# NUC1261AE_v1 register map
File version: 1.0
Registers are 32-bit, read-write, reset 0x0 unless marked. A register's access mark holds for its fields unless they carry their own. Offsets are from the block's base; [hi:lo] are bit positions; lines under a group give offsets from that group; {n}, {i} and the like mark numbered series; 'fields as' and 'values as' point back to an identical list.

## PWM0 — PWM Register Map
Base 0x40040000
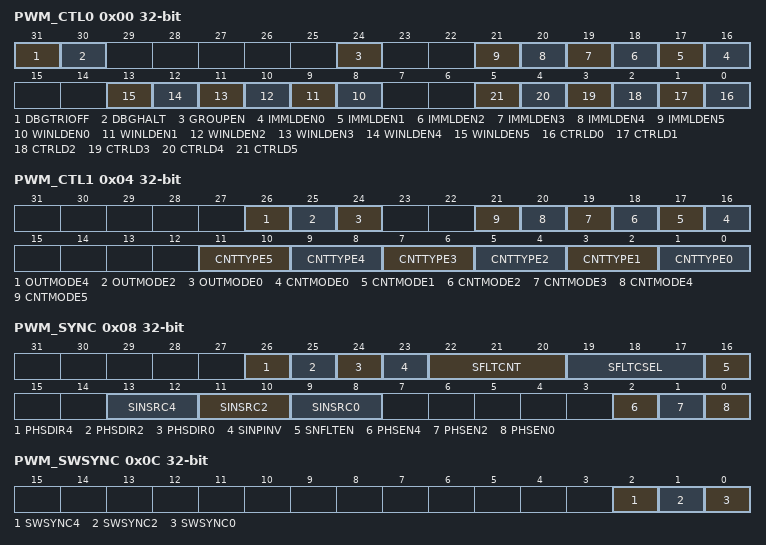
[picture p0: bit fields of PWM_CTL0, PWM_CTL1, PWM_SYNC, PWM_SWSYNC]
0x00 PWM_CTL0 — PWM Control Register 0
  [31] DBGTRIOFF — ICE Debug Mode Acknowledge Disable (Write Protect). PWM pin will keep output no matter ICE debug mode acknowledged or not. Note: This bit is write protected. Refer to SYS_REGLCTL register.
    0=ICE debug mode acknowledgement effects PWM output; 1=ICE debug mode acknowledgement Disabled
  [30] DBGHALT — ICE Debug Mode Counter Halt (Write Protect). If counter halt is enabled, PWM all counters will keep current value until exit ICE debug mode. Note: This bit is write protected. Refer to SYS_REGLCTL register.
    0=ICE debug mode counter halt Disabled; 1=ICE debug mode counter halt Enabled
  [24] GROUPEN — Group Function Enable Bit
    0=The output waveform of each PWM channel are independent; 1=Unify the PWMx_CH2 and PWMx_CH4 to output the same waveform as PWMx_CH0 and unify the PWMx_CH3 and PWMx_CH5 to output the same waveform as PWMx_CH1
  [n+16] IMMLDEN{n} (n=0..5) — Immediately Load Enable Bits. Each bit n controls the corresponding PWM channel n. Note: If IMMLDENn bit is enabled, WINLDENn bit and CTRLDn bits will be invalid.
    0=PERIODn register will load to PBUFn register at the end point of each period. CMPDATn register will load to CMPBUFn register at the end point or center point of each period by setting CTRLDn bit; 1=PERIODn/CMPDATn registers will load to PBUFn and CMPBUFn register immediately when software update PERIODn/CMPDATn register
  [n+8] WINLDEN{n} (n=0..5) — Window Load Enable Bits. Each bit n controls the corresponding PWM channel n.
    0=PERIODn register will load to PBUFn register at the end point of each period. CMPDATn register will load to CMPBUFn register at the end point or center point of each period by setting CTRLDn bit; 1=PERIODn register will load to PBUFn and CMPDATn registers will load to CMPBUFn register at the end point of each period when valid reload window is set. The valid reload window is set by software write 1 to PWM_LOAD register, and cleared by hardware after load success
  [n] CTRLD{n} (n=0..5) — Center Re-load. Each bit n controls the corresponding PWM channel n. In up-down counter type, PERIODn register will load to PBUFn register at the end point of each period. CMPDATn register will load to CMPBUFn register at the center point of a period.
0x04 PWM_CTL1 — PWM Control Register 1
  [26] OUTMODE4 — PWM Output Mode. Each bit n controls the output mode of corresponding PWM channel n. Note: When operating in group function, these bits must all set to the same mode.
    0=PWM independent mode; 1=PWM complementary mode
  [25] OUTMODE2 — PWM Output Mode. Each bit n controls the output mode of corresponding PWM channel n. Note: When operating in group function, these bits must all set to the same mode.
    0=PWM independent mode; 1=PWM complementary mode
  [24] OUTMODE0 — PWM Output Mode. Each bit n controls the output mode of corresponding PWM channel n. Note: When operating in group function, these bits must all set to the same mode.
    0=PWM independent mode; 1=PWM complementary mode
  [n+16] CNTMODE{n} (n=0..5) — PWM Counter Mode. Each bit n controls the corresponding PWM channel n.
    0=Auto-reload mode; 1=One-shot mode
  [2n+1:2n] CNTTYPE{n} (n=0..5) — PWM Counter Behavior Type. Each bit n controls corresponding PWM channel n.
    0=Up counter type (supports in capture mode); 1=Down count type (supports in capture mode); 2=Up-down counter type
0x08 PWM_SYNC — PWM Synchronization Register
  [26] PHSDIR4 — PWM Phase Direction Control. Each bit n controls corresponding PWM channel n.
    0=Control PWM counter count decrement after synchronizing; 1=Control PWM counter count increment after synchronizing
  [25] PHSDIR2 — PWM Phase Direction Control. Each bit n controls corresponding PWM channel n.
    values as PHSDIR4
  [24] PHSDIR0 — PWM Phase Direction Control. Each bit n controls corresponding PWM channel n.
    values as PHSDIR4
  [23] SINPINV — SYNC Input Pin Inverse
    0=The state of PWM0_SYNC_IN pin is passed to the negative edge detector; 1=The inversed state of PWM0_SYNC_IN pin is passed to the negative edge detector
  [22:20] SFLTCNT — SYNC Edge Detector Filter Count. The register bits control the counter number of edge detector.
  [19:17] SFLTCSEL — SYNC Edge Detector Filter Clock Selection
    0=Filter clock = HCLK; 1=Filter clock = HCLK/2; 2=Filter clock = HCLK/4; 3=Filter clock = HCLK/8; 4=Filter clock = HCLK/16; 5=Filter clock = HCLK/32; 6=Filter clock = HCLK/64; 7=Filter clock = HCLK/128
  [16] SNFLTEN — PWM0_SYNC_IN Noise Filter Enable Bit
    0=Noise filter of input PWM0_SYNC_IN pin Disabled; 1=Noise filter of input PWM0_SYNC_IN pin Enabled
  [13:12] SINSRC4 — PWM0_SYNC_IN Source Selection. Each bit n controls corresponding PWM channel n.
    0=Synchronize source from SYNC_IN or SWSYNC; 1=Counter equal to 0; 2=Counter equal to PWM_CMPDATm, m denotes 1, 3, 5; 3=SYNC_OUT signal will not be generated
  [11:10] SINSRC2 — PWM0_SYNC_IN Source Selection. Each bit n controls corresponding PWM channel n.
    values as SINSRC4
  [9:8] SINSRC0 — PWM0_SYNC_IN Source Selection. Each bit n controls corresponding PWM channel n.
    values as SINSRC4
  [2] PHSEN4 — SYNC Phase Enable Bits n denotes PWM channel 0,2,4 and m denotes channel 1,3,5.
    0=PWM counter disable to load value of PHS(PWM_PHSn_m[15:0]) bits; 1=PWM counter enable to load value of PHS(PWM_PHSn_m[15:0]) bits
  [1] PHSEN2 — SYNC Phase Enable Bits n denotes PWM channel 0,2,4 and m denotes channel 1,3,5.
    values as PHSEN4
  [0] PHSEN0 — SYNC Phase Enable Bits n denotes PWM channel 0,2,4 and m denotes channel 1,3,5.
    values as PHSEN4
0x0C PWM_SWSYNC — PWM Software Control Synchronization Register
  [2] SWSYNC4 — Software SYNC Function. Each bit n controls corresponding PWM channel n. When SINSRCn (PWM_SYNC[13:8]) is selected to 0, SYNC_OUT source is come from SYNC_IN or this bit.
  [1] SWSYNC2 — Software SYNC Function. Each bit n controls corresponding PWM channel n. When SINSRCn (PWM_SYNC[13:8]) is selected to 0, SYNC_OUT source is come from SYNC_IN or this bit.
  [0] SWSYNC0 — Software SYNC Function. Each bit n controls corresponding PWM channel n. When SINSRCn (PWM_SYNC[13:8]) is selected to 0, SYNC_OUT source is come from SYNC_IN or this bit.
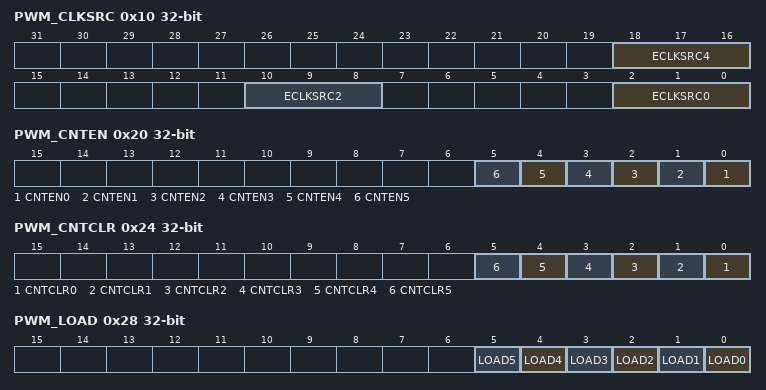
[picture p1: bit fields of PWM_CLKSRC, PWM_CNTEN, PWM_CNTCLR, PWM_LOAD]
0x10 PWM_CLKSRC — PWM Clock Source Register
  [all] fields
    0=PWMx_CLK, x denotes 0 or 1; {v}=TIMER{v-1} time-out event (v=1..4)
  [18:16] ECLKSRC4 — PWMx_CH4/5 External Clock Source Select
  [10:8] ECLKSRC2 — PWMx_CH2/3 External Clock Source Select
  [2:0] ECLKSRC0 — PWMx_CH0/1 External Clock Source Select
0x14 PWM_CLKPSC0_1 — PWM Clock Pre-scale Register 0/1
  [11:0] CLKPSC — PWM Counter Clock Pre-scale. The clock of PWM counter is decided by clock prescaler. Each PWM pair share one PWM counter clock prescaler. The clock of PWM counter is divided by (CLKPSC+ 1).
0x18 PWM_CLKPSC2_3 — PWM Clock Pre-scale Register 2/3
  fields as PWM_CLKPSC0_1
0x1C PWM_CLKPSC4_5 — PWM Clock Pre-scale Register 4/5
  fields as PWM_CLKPSC0_1
0x20 PWM_CNTEN — PWM Counter Enable Register
  [all] fields
    0=PWM Counter and clock prescaler Stop Running; 1=PWM Counter and clock prescaler Start Running
  [n] CNTEN{n} (n=0..5) — PWM Counter Enable Bits. Each bit n controls the corresponding PWM channel n.
0x24 PWM_CNTCLR — PWM Clear Counter Register
  [all] fields
    0=No effect; 1=Clear 16-bit PWM counter to 0x0000(CNT(PWM_CNTn[15:0]))
  [n] CNTCLR{n} (n=0..5) — Clear PWM Counter Control Bit. It is automatically cleared by hardware. Each bit n controls the corresponding PWM channel n.
0x28 PWM_LOAD
  [all] fields
    0=No effect. No load window is set; 1=Set load window of window loading mode. Load window is set
  [n] LOAD{n} (n=0..5) — Re-load PWM Comparator Register (CMPDAT) Control Bit. This bit is software write, and hardware clear when current PWM period end. Each bit n controls the corresponding PWM channel n. Write Operation:
{0x30+4i} PWM_PERIOD{i} (i=0..5) — PWM Period Register {i}
  [15:0] PERIOD — PWM Period Register. Up-Count mode: In this mode, PWM counter counts from 0 to PERIOD, and restarts from 0.
{0x50+4i} PWM_CMPDAT{i} (i=0..5) — PWM Comparator Register {i}
  [15:0] CMP — PWM Comparator Register. CMP bits use to compare with CNT(PWM_CNTn[15:0]) bits to generate PWM waveform, interrupt and trigger ADC. In independent mode, CMPDAT0~5 registers denote as 6 independent PWMx_CH0~5 compared point. In complementary mode, CMPDAT0, 2, 4 registers denote as first compared point, and CMPDAT1, 3, 5 register denote as second compared point for the corresponding 3 complementary pairs PWMx_CH0 and PWMx_CH1, PWMx_CH2 and PWMx_CH3, PWMx_CH4 and PWMx_CH5.
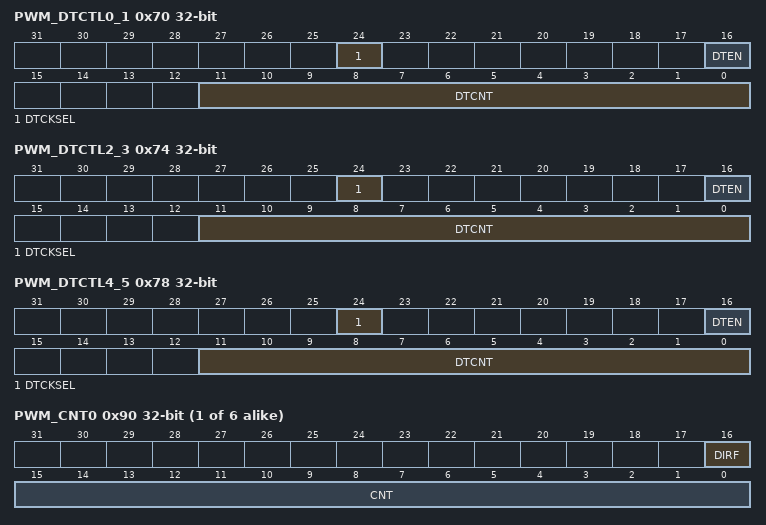
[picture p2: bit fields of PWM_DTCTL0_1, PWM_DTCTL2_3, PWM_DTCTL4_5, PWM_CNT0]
0x70 PWM_DTCTL0_1 — PWM Dead-time Control Register 0/1
  [24] DTCKSEL — Dead-time Clock Select (Write Protect). Note: This register is write protected. Refer to SYS_REGLCTL register.
    0=Dead-time clock source from PWMx_CLK without counter clock prescale; 1=Dead-time clock source from prescaler output with counter clock prescale
  [16] DTEN — Enable Dead-time Insertion for PWM Pair (PWMx_CH0, PWMx_CH1) (PWMx_CH2, PWMx_CH3) (PWMx_CH4, PWMx_CH5) (Write Protect). Dead-time insertion is only active when this pair of complementary PWM is enabled. If dead- time insertion is inactive, the outputs of pin pair are complementary without any delay. Note: This register is write protected. Refer to SYS_REGLCTL register.
    0=Dead-time insertion Disabled on the pin pair; 1=Dead-time insertion Enabled on the pin pair
  [11:0] DTCNT — Dead-time Counter (Write Protect). The dead-time can be calculated from the following formula: Note: This register is write protected. Refer to SYS_REGLCTL register.
0x74 PWM_DTCTL2_3 — PWM Dead-time Control Register 2/3
  fields as PWM_DTCTL0_1
0x78 PWM_DTCTL4_5 — PWM Dead-time Control Register 4/5
  fields as PWM_DTCTL0_1
0x80 PWM_PHS0_1 — PWM Counter Phase Register 0/1
  [15:0] PHS — PWM Synchronous Start Phase Bits. PHS bits determines the PWM synchronous start phase value. These bits only use in synchronous function.
0x84 PWM_PHS2_3 — PWM Counter Phase Register 2/3
  fields as PWM_PHS0_1
0x88 PWM_PHS4_5 — PWM Counter Phase Register 4/5
  fields as PWM_PHS0_1
{0x90+4i} PWM_CNT{i} ro (i=0..5) — PWM Counter Register {i}
  [16] DIRF — PWM Direction Indicator Flag (Read Only)
    0=Counter is Down count; 1=Counter is UP count
  [15:0] CNT — PWM Counter Data Bits (Read Only). User can monitor CNT to know the current value in 16-bit period counter.
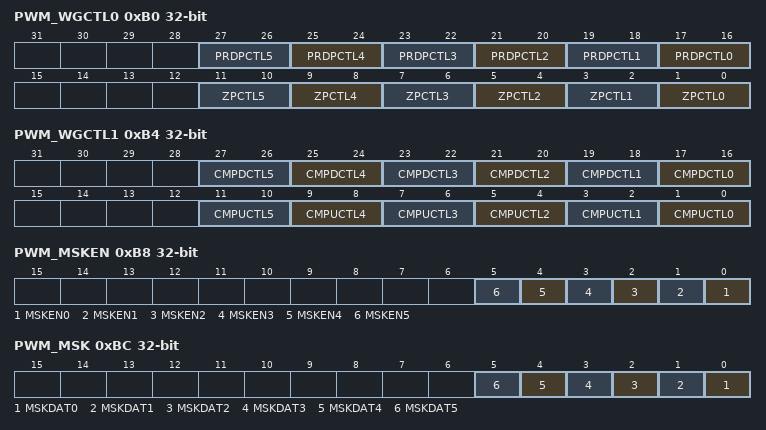
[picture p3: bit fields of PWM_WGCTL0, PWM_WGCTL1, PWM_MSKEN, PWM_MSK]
0xB0 PWM_WGCTL0 — PWM Generation Register 0
  [2n+17:2n+16] PRDPCTL{n} (n=0..5) — PWM Period (Center) Point Control. PWM can control output level on period(center) point event. Each bit n controls the corresponding PWM channel n. Note: This bit is center point control when PWM counter operating in up-down counter type.
    0=Do nothing; 1=PWM period (center) point output Low; 2=PWM period (center) point output High; 3=PWM period (center) point output Toggle
  [2n+1:2n] ZPCTL{n} (n=0..5) — PWM Zero Point Control. PWM can control output level on zero point event. Each bit n controls the corresponding PWM channel n.
    0=Do nothing; 1=PWM zero point output Low; 2=PWM zero point output High; 3=PWM zero point output Toggle
0xB4 PWM_WGCTL1 — PWM Generation Register 1
  [2n+17:2n+16] CMPDCTL{n} (n=0..5) — PWM Compare Down Point Control. PWM can control output level on compare down point event. Each bit n controls the corresponding PWM channel n. Note: In complementary mode, CMPDCTL1, 3, 5 is used as another CMPDCTL for channel 0, 2, 4.
    0=Do nothing; 1=PWM compare down point output Low; 2=PWM compare down point output High; 3=PWM compare down point output Toggle
  [2n+1:2n] CMPUCTL{n} (n=0..5) — PWM Compare Up Point Control. PWM can control output level on compare up point event. Each bit n controls the corresponding PWM channel n. Note: In complementary mode, CMPUCTL1, 3, 5 is used as another CMPUCTL for channel 0, 2, 4.
    0=Do nothing; 1=PWM compare up point output Low; 2=PWM compare up point output High; 3=PWM compare up point output Toggle
0xB8 PWM_MSKEN — PWM Mask Enable Register
  [all] fields
    0=PWM output signal is non-masked; 1=PWM output signal is masked and output MSKDATn data
  [n] MSKEN{n} (n=0..5) — PWM Mask Enable Bits. The PWM output signal will be masked when this bit is enabled. The corresponding PWM channel n will output MSKDATn (PWM_MSK[5:0]) data. Each bit n controls the corresponding PWM channel n.
0xBC PWM_MSK — PWM Mask Data Register
  [all] fields
    0=Output logic low to PWMx_CHn; 1=Output logic high to PWMx_CHn
  [n] MSKDAT{n} (n=0..5) — PWM Mask Data Bit. This data bit control the state of PWMx_CHn output pin, if corresponding mask function is enabled. Each bit n controls the corresponding PWM channel n.
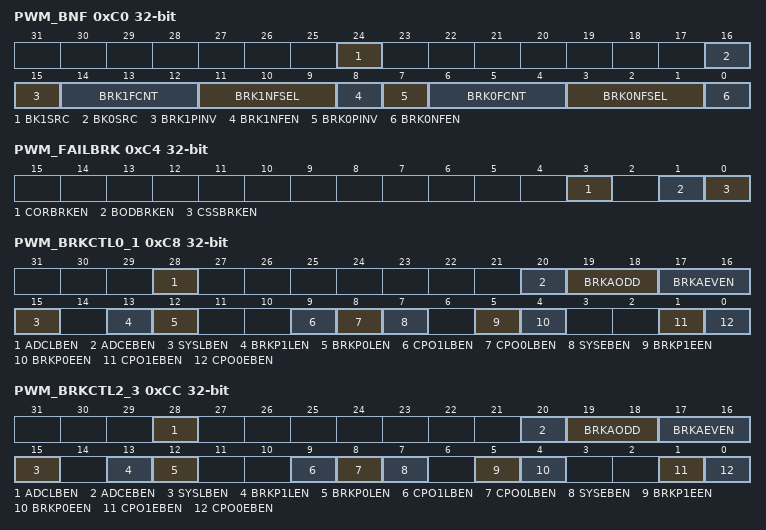
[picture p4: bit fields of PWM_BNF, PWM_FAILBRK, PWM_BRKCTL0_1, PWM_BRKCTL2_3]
0xC0 PWM_BNF — PWM Brake Noise Filter Register
  [24] BK1SRC — Brake 1 Pin Source Select. For PWM0 setting:
    0=Brake 1 pin source come from PWM0_BRAKE1. Brake 1 pin source come from PWM1_BRAKE1; 1=Brake 1 pin source come from PWM1_BRAKE1. Brake 1 pin source come from PWM0_BRAKE1
  [16] BK0SRC — Brake 0 Pin Source Select. For PWM0 setting:
    0=Brake 0 pin source come from PWM0_BRAKE0. Brake 0 pin source come from PWM1_BRAKE0; 1=Brake 0 pin source come from PWM1_BRAKE0. Brake 0 pin source come from PWM0_BRAKE0
  [15] BRK1PINV — Brake 1 Pin Inverse
    0=Brake pin event will be detected if PWM1_BRAKEx pin status transfer from low to high in edge-detect, or pin status is high in level-detect; 1=Brake pin event will be detected if PWM1_BRAKEx pin status transfer from high to low in edge-detect, or pin status is low in level-detect
  [14:12] BRK1FCNT — Brake 1 Edge Detector Filter Count. The register bits control the Brake1 filter counter to count from 0 to BRK1FCNT.
  [11:9] BRK1NFSEL — Brake 1 Edge Detector Filter Clock Selection
    values as PWM_SYNC.SFLTCSEL
  [8] BRK1NFEN — PWM Brake 1 Noise Filter Enable Bit
    0=Noise filter of PWM Brake 1 Disabled; 1=Noise filter of PWM Brake 1 Enabled
  [7] BRK0PINV — Brake 0 Pin Inverse
    0=Brake pin event will be detected if PWM0_BRAKEx pin status transfer from low to high in edge-detect, or pin status is high in level-detect; 1=Brake pin event will be detected if PWM0_BRAKEx pin status transfer from high to low in edge-detect, or pin status is low in level-detect
  [6:4] BRK0FCNT — Brake 0 Edge Detector Filter Count. The register bits control the Brake0 filter counter to count from 0 to BRK0FCNT.
  [3:1] BRK0NFSEL — Brake 0 Edge Detector Filter Clock Selection
    values as PWM_SYNC.SFLTCSEL
  [0] BRK0NFEN — PWM Brake 0 Noise Filter Enable Bit
    0=Noise filter of PWM Brake 0 Disabled; 1=Noise filter of PWM Brake 0 Enabled
0xC4 PWM_FAILBRK — PWM System Fail Brake Control Register
  [3] CORBRKEN — Core Lockup Detection Trigger PWM Brake Function Enable Bit
    0=Brake Function triggered by Core lockup event Disabled; 1=Brake Function triggered by Core lockup event Enabled
  [1] BODBRKEN — Brown-out Detection Trigger PWM Brake Function Enable Bit
    0=Brake Function triggered by BOD event Disabled; 1=Brake Function triggered by BOD event Enabled
  [0] CSSBRKEN — Clock Security System Detection Trigger PWM Brake Function Enable Bit
    0=Brake Function triggered by clock fail detection Disabled; 1=Brake Function triggered by clock fail detection Enabled
0xC8 PWM_BRKCTL0_1 — PWM Brake Edge Detect Control Register 0/1
  [28] ADCLBEN — Enable ADC Result Monitor (ADCRM) As Level-detect Brake Source (Write Protect). Note: This register is write protected. Refer to SYS_REGLCTL register.
    0=ADCRM as level-detect brake source Disabled; 1=ADCRM as level-detect brake source Enabled
  [20] ADCEBEN — Enable ADC Result Monitor (ADCRM) As Edge-detect Brake Source (Write Protect). Note: This register is write protected. Refer to SYS_REGLCTL register.
    0=ADCRM as edge-detect brake source Disabled; 1=ADCRM as edge-detect brake source Enabled
  [19:18] BRKAODD — PWM Brake Action Select for Odd Channel (Write Protect). Note: This register is write protected. Refer to SYS_REGLCTL register.
    0=PWMx brake event will not affect odd channels output; 1=PWM odd channel output tri-state when PWMx brake event happened; 2=PWM odd channel output low level when PWMx brake event happened; 3=PWM odd channel output high level when PWMx brake event happened
  [17:16] BRKAEVEN — PWM Brake Action Select for Even Channel (Write Protect). Note: This register is write protected. Refer to SYS_REGLCTL register.
    0=PWMx brake event will not affect even channels output; 1=PWM even channel output tri-state when PWMx brake event happened; 2=PWM even channel output low level when PWMx brake event happened; 3=PWM even channel output high level when PWMx brake event happened
  [15] SYSLBEN — Enable System Fail As Level-detect Brake Source (Write Protect). Note: This register is write protected. Refer to SYS_REGLCTL register.
    0=System Fail condition as level-detect brake source Disabled; 1=System Fail condition as level-detect brake source Enabled
  [13] BRKP1LEN — Enable BKP1 Pin As Level-detect Brake Source (Write Protect). Note: This register is write protected. Refer to SYS_REGLCTL register.
    0=PWMx_BRAKE1 pin as level-detect brake source Disabled; 1=PWMx_BRAKE1 pin as level-detect brake source Enabled
  [12] BRKP0LEN — Enable BKP0 Pin As Level-detect Brake Source (Write Protect). Note: This register is write protected. Refer to SYS_REGLCTL register.
    0=PWMx_BRAKE0 pin as level-detect brake source Disabled; 1=PWMx_BRAKE0 pin as level-detect brake source Enabled
  [9] CPO1LBEN — Enable ACMP1_O Digital Output As Level-detect Brake Source (Write Protect). Note: This register is write protected. Refer to SYS_REGLCTL register.
    0=ACMP1_O as level-detect brake source Disabled; 1=ACMP1_O as level-detect brake source Enabled
  [8] CPO0LBEN — Enable ACMP0_O Digital Output As Level-detect Brake Source (Write Protect). Note: This register is write protected. Refer to SYS_REGLCTL register.
    0=ACMP0_O as level-detect brake source Disabled; 1=ACMP0_O as level-detect brake source Enabled
  [7] SYSEBEN — Enable System Fail As Edge-detect Brake Source (Write Protect). Note: This register is write protected. Refer to SYS_REGLCTL register.
    0=System Fail condition as edge-detect brake source Disabled; 1=System Fail condition as edge-detect brake source Enabled
  [5] BRKP1EEN — Enable PWMx_BRAKE1 Pin As Edge-detect Brake Source (Write Protect). Note: This register is write protected. Refer to SYS_REGLCTL register.
    0=PWMx_BRAKE1 pin as edge-detect brake source Disabled; 1=PWMx_BRAKE1 pin as edge-detect brake source Enabled
  [4] BRKP0EEN — Enable PWMx_BRAKE0 Pin As Edge-detect Brake Source (Write Protect). Note: This register is write protected. Refer to SYS_REGLCTL register.
    0=PWMx_BRAKE0 pin as edge-detect brake source Disabled; 1=PWMx_BRAKE0 pin as edge-detect brake source Enabled
  [1] CPO1EBEN — Enable ACMP1_O Digital Output As Edge-detect Brake Source (Write Protect). Note: This register is write protected. Refer to SYS_REGLCTL register.
    0=ACMP1_O as edge-detect brake source Disabled; 1=ACMP1_O as edge-detect brake source Enabled
  [0] CPO0EBEN — Enable ACMP0_O Digital Output As Edge-detect Brake Source (Write Protect). Note: This register is write protected. Refer to SYS_REGLCTL register.
    0=ACMP0_O as edge-detect brake source Disabled; 1=ACMP0_O as edge-detect brake source Enabled
0xCC PWM_BRKCTL2_3 — PWM Brake Edge Detect Control Register 2/3
  fields as PWM_BRKCTL0_1
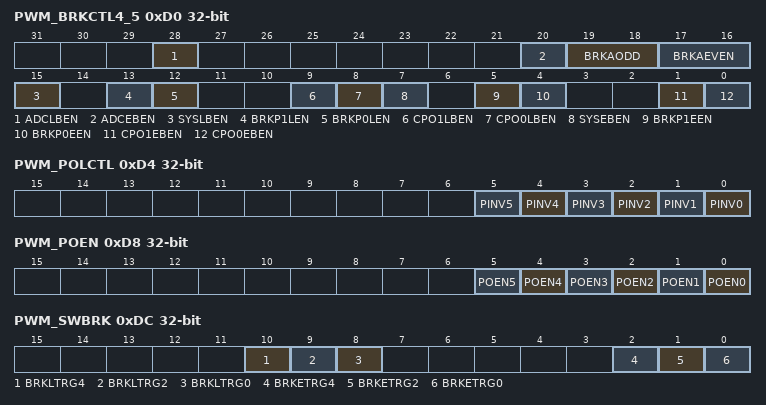
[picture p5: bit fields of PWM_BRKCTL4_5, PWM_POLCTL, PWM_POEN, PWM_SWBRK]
0xD0 PWM_BRKCTL4_5 — PWM Brake Edge Detect Control Register 4/5
  fields as PWM_BRKCTL0_1
0xD4 PWM_POLCTL — PWM Pin Polar Inverse Register
  [all] fields
    0=PWMx_CHn output pin polar inverse Disabled; 1=PWMx_CHn output pin polar inverse Enabled
  [n] PINV{n} (n=0..5) — PWM PIN Polar Inverse Control. The register controls polarity state of PWMx_CHn output pin. Each bit n controls the corresponding PWM channel n.
0xD8 PWM_POEN — PWM Output Enable Register
  [all] fields
    0=PWMx_CHn pin at tri-state; 1=PWMx_CHn pin in output mode
  [n] POEN{n} (n=0..5) — PWMx_CHn Pin Output Enable Bits. Each bit n controls the corresponding PWM channel n.
0xDC PWM_SWBRK wo — PWM Software Brake Control Register
  [10] BRKLTRG4 — PWM Level Brake Software Trigger (Write Only) (Write Protect). Write 1 to this bit will trigger level brake, and set BRKLIFn bits to 1 in PWM_INTSTS1 register. Each bit n controls the corresponding PWM pair n. Note: This register is write protected. Refer to SYS_REGLCTL register.
  [9] BRKLTRG2 — PWM Level Brake Software Trigger (Write Only) (Write Protect). Write 1 to this bit will trigger level brake, and set BRKLIFn bits to 1 in PWM_INTSTS1 register. Each bit n controls the corresponding PWM pair n. Note: This register is write protected. Refer to SYS_REGLCTL register.
  [8] BRKLTRG0 — PWM Level Brake Software Trigger (Write Only) (Write Protect). Write 1 to this bit will trigger level brake, and set BRKLIFn bits to 1 in PWM_INTSTS1 register. Each bit n controls the corresponding PWM pair n. Note: This register is write protected. Refer to SYS_REGLCTL register.
  [2] BRKETRG4 — PWM Edge Brake Software Trigger (Write Only) (Write Protect). Write 1 to this bit will trigger Edge brake, and set BRKEIFn bits to 1 in PWM_INTSTS1 register. Each bit n controls the corresponding PWM pair n. Note: This register is write protected. Refer to REGWRPROT register.
  [1] BRKETRG2 — PWM Edge Brake Software Trigger (Write Only) (Write Protect). Write 1 to this bit will trigger Edge brake, and set BRKEIFn bits to 1 in PWM_INTSTS1 register. Each bit n controls the corresponding PWM pair n. Note: This register is write protected. Refer to REGWRPROT register.
  [0] BRKETRG0 — PWM Edge Brake Software Trigger (Write Only) (Write Protect). Write 1 to this bit will trigger Edge brake, and set BRKEIFn bits to 1 in PWM_INTSTS1 register. Each bit n controls the corresponding PWM pair n. Note: This register is write protected. Refer to REGWRPROT register.
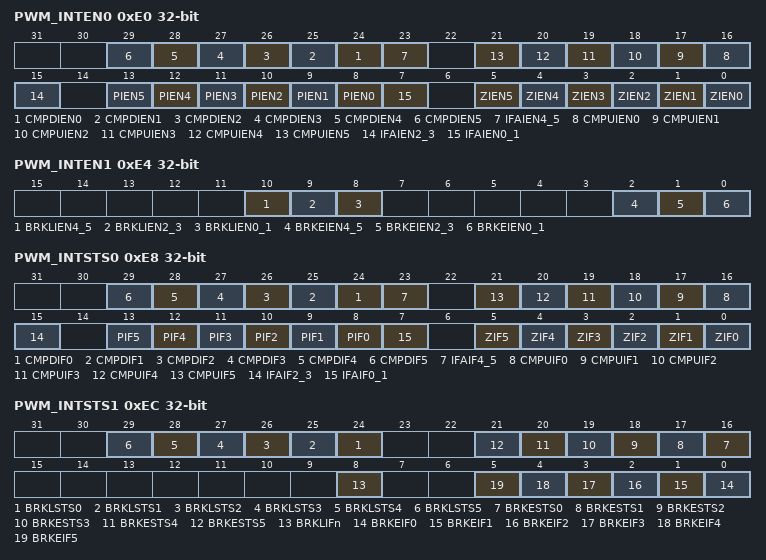
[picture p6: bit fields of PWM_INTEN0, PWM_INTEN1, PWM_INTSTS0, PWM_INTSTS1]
0xE0 PWM_INTEN0 — PWM Interrupt Enable Register 0
  [n+24] CMPDIEN{n} (n=0..5) — PWM Compare Down Count Interrupt Enable Bits. Each bit n controls the corresponding PWM channel n. Note: In complementary mode, CMPDIEN1, 3, 5 is used as another CMPDIEN for channel 0, 2, 4.
    0=Compare down count interrupt Disabled; 1=Compare down count interrupt Enabled
  [23] IFAIEN4_5 — PWM Channel 4/5 Interrupt Flag Accumulator Interrupt Enable Bit
    0=Interrupt Flag accumulator interrupt Disabled; 1=Interrupt Flag accumulator interrupt Enabled
  [n+16] CMPUIEN{n} (n=0..5) — PWM Compare Up Count Interrupt Enable Bits. Each bit n controls the corresponding PWM channel n. Note: In complementary mode, CMPUIEN1, 3, 5 is used as another CMPUIEN for channel 0, 2, 4.
    0=Compare up count interrupt Disabled; 1=Compare up count interrupt Enabled
  [15] IFAIEN2_3 — PWM Channel 2/3 Interrupt Flag Accumulator Interrupt Enable Bit
    values as IFAIEN4_5
  [n+8] PIEN{n} (n=0..5) — PWM Period Point Interrupt Enable Bits. Each bit n controls the corresponding PWM channel n. Note1: When up-down counter type period point means center point. Note2: Odd channels will read always 0 at complementary mode.
    0=Period point interrupt Disabled; 1=Period point interrupt Enabled
  [7] IFAIEN0_1 — PWM Channel 0/1 Interrupt Flag Accumulator Interrupt Enable Bit
    values as IFAIEN4_5
  [n] ZIEN{n} (n=0..5) — PWM Zero Point Interrupt Enable Bits. Each bit n controls the corresponding PWM channel n. Note: Odd channels will read always 0 at complementary mode.
    0=Zero point interrupt Disabled; 1=Zero point interrupt Enabled
0xE4 PWM_INTEN1 — PWM Interrupt Enable Register 1
  [10] BRKLIEN4_5 — PWM Level-detect Brake Interrupt Enable for Channel4/5 (Write Protect). Note: This register is write protected. Refer to SYS_REGLCTL register.
    0=Level-detect Brake interrupt for channel4/5 Disabled; 1=Level-detect Brake interrupt for channel4/5 Enabled
  [9] BRKLIEN2_3 — PWM Level-detect Brake Interrupt Enable for Channel2/3 (Write Protect). Note: This register is write protected. Refer to SYS_REGLCTL register.
    0=Level-detect Brake interrupt for channel2/3 Disabled; 1=Level-detect Brake interrupt for channel2/3 Enabled
  [8] BRKLIEN0_1 — PWM Level-detect Brake Interrupt Enable for Channel0/1 (Write Protect). Note: This register is write protected. Refer to SYS_REGLCTL register.
    0=Level-detect Brake interrupt for channel0/1 Disabled; 1=Level-detect Brake interrupt for channel0/1 Enabled
  [2] BRKEIEN4_5 — PWM Edge-detect Brake Interrupt Enable for Channel4/5 (Write Protect). Note: This register is write protected. Refer to SYS_REGLCTL register.
    0=Edge-detect Brake interrupt for channel4/5 Disabled; 1=Edge-detect Brake interrupt for channel4/5 Enabled
  [1] BRKEIEN2_3 — PWM Edge-detect Brake Interrupt Enable for Channel2/3 (Write Protect). Note: This register is write protected. Refer to SYS_REGLCTL register.
    0=Edge-detect Brake interrupt for channel2/3 Disabled; 1=Edge-detect Brake interrupt for channel2/3 Enabled
  [0] BRKEIEN0_1 — PWM Edge-detect Brake Interrupt Enable for Channel0/1 (Write Protect). Note: This register is write protected. Refer to SYS_REGLCTL register.
    0=Edge-detect Brake interrupt for channel0/1 Disabled; 1=Edge-detect Brake interrupt for channel0/1 Enabled
0xE8 PWM_INTSTS0 — PWM Interrupt Flag Register 0
  [n+24] CMPDIF{n} (n=0..5) — PWM Compare Down Count Interrupt Flag. Flag is set by hardware when PWM counter down count and reaches CMP(PWM_CMPDATn[15:0]), software can clear this bit by writing 1 to it. Each bit n controls the corresponding PWM channel n. Note1: If CMP equal to PERIOD, this flag is not working in down counter type selection. Note2: In complementary mode, CMPDIF1, 3, 5 is used as another CMPDIF for channel 0, 2, 4.
  [23] IFAIF4_5 — PWM Channel 4/5 Interrupt Flag Accumulator Interrupt Flag. Flag is set by hardware when condition match IFSEL4_5 bits in PWM_IFA register, software can clear this bit by writing 1 to it.
  [n+16] CMPUIF{n} (n=0..5) — PWM Compare Up Count Interrupt Flag. Flag is set by hardware when PWM counter up count and reaches CMP(PWM_CMPDATn[15:0]), software can clear this bit by writing 1 to it. Each bit n controls the corresponding PWM channel n. Note1: If CMP equal to PERIOD, this flag is not working in up counter type selection. Note2: In complementary mode, CMPUIF1, 3, 5 is used as another CMPUIF for channel 0, 2, 4.
  [15] IFAIF2_3 — PWM Channel 2/3 Interrupt Flag Accumulator Interrupt Flag. Flag is set by hardware when condition match IFSEL2_3 bits in PWM_IFA register, software can clear this bit by writing 1 to it.
  [n+8] PIF{n} (n=0..5) — PWM Period Point Interrupt Flag. This bit is set by hardware when PWM counter reaches PERIOD(PWM_PERIODn[15:0]), software can write 1 to clear this bit to zero. Each bit n controls the corresponding PWM channel n.
  [7] IFAIF0_1 — PWM Channel 0/1 Interrupt Flag Accumulator Interrupt Flag. Flag is set by hardware when condition match IFSEL0_1 bits in PWM_IFA register, software can clear this bit by writing 1 to it.
  [n] ZIF{n} (n=0..5) — PWM Zero Point Interrupt Flag. Each bit n controls the corresponding PWM channel n. This bit is set by hardware when PWM counter reaches zero, software can write 1 to clear this bit to zero.
0xEC PWM_INTSTS1 — PWM Interrupt Flag Register 1
  [n+24] BRKLSTS{n} ro (n=0..5) — PWM Channel n Level-detect Brake Status (Read Only). Note: This bit is read only and auto cleared by hardware. When enabled brake source return to high level, PWM will release brake state until current PWM period finished. The PWM waveform will start output from next full PWM period.
    0=PWM channel n level-detect brake state is released; 1=When PWM channel n level-detect brake detects a falling edge of any enabled brake source; this flag will be set to indicate the PWM channel n at brake state
  [n+16] BRKESTS{n} (n=0..5) — PWM Channel n Edge-detect Brake Status
    0=PWM channel n edge-detect brake state is released; 1=When PWM channel n edge-detect brake detects a falling edge of any enabled brake source; this flag will be set to indicate the PWM channel n at brake state, writing 1 to clear
  [8] BRKLIFn — PWM Channel n Level-detect Brake Interrupt Flag (Write Protect). Note: This bit is write protected. Refer to SYS_REGLCTL register.
    0=PWM channel n level-detect brake event do not happened; 1=When PWM channel n level-detect brake event happened, this bit is set to 1, writing 1 to clear
  [n] BRKEIF{n} (n=0..5) — PWM Channel n Edge-detect Brake Interrupt Flag (Write Protect). Note: This bit is write protected. Refer to SYS_REGLCTL register.
    0=PWM channel n edge-detect brake event do not happened; 1=When PWM channel n edge-detect brake event happened, this bit is set to 1, writing 1 to clear
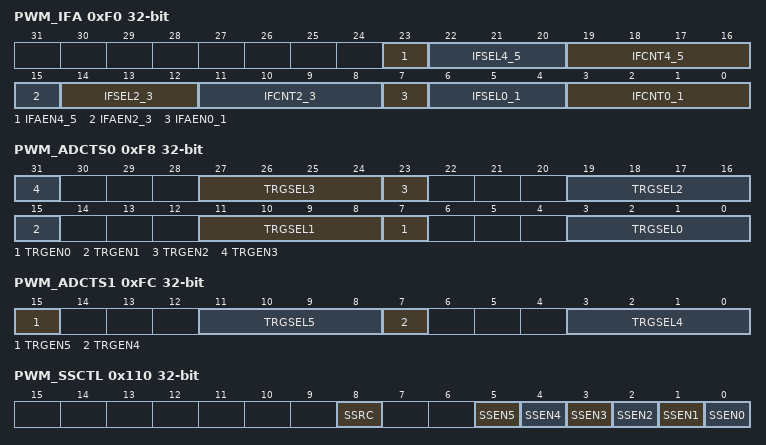
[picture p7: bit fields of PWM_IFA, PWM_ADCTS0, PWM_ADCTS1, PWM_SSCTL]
0xF0 PWM_IFA — PWM Interrupt Flag Accumulator Register
  [23] IFAEN4_5 — PWM Channel 4/5 Interrupt Flag Accumulator Enable Bit
    0=PWM Channel 4/5 interrupt flag accumulator Disabled; 1=PWM Channel 4/5 interrupt flag accumulator Enabled
  [22:20] IFSEL4_5 — PWM Channel 4/5 Interrupt Flag Accumulator Source Select
    0=CNT equal to Zero in channel 4; 1=CNT equal to PERIOD in channel 4; 2=CNT equal to CMPU in channel 4; 3=CNT equal to CMPD in channel 4; 4=CNT equal to Zero in channel 5; 5=CNT equal to PERIOD in channel 5; 6=CNT equal to CMPU in channel 5; 7=CNT equal to CMPD in channel 5
  [19:16] IFCNT4_5 — PWM Channel 4/5 Interrupt Flag Counter. The register sets the count number which defines how many times of PWM Channel 4/5 period occurs to set IFAIF4_5 bit to request the PWM period interrupt. PWM flag will be set in every IFCNT4_5[3:0] times of PWM period.
  [15] IFAEN2_3 — PWM Channel 2/3 Interrupt Flag Accumulator Enable Bit
    0=PWM Channel 2/3 interrupt flag accumulator Disabled; 1=PWM Channel 2/3 interrupt flag accumulator Enabled
  [14:12] IFSEL2_3 — PWM Channel 2/3 Interrupt Flag Accumulator Source Select
    0=CNT equal to Zero in channel 2; 1=CNT equal to PERIOD in channel 2; 2=CNT equal to CMPU in channel 2; 3=CNT equal to CMPD in channel 2; 4=CNT equal to Zero in channel 3; 5=CNT equal to PERIOD in channel 3; 6=CNT equal to CMPU in channel 3; 7=CNT equal to CMPD in channel 3
  [11:8] IFCNT2_3 — PWM Channel 2/3 Interrupt Flag Counter. The register sets the count number which defines how many times of PWM Channel 2/3 period occurs to set IFAIF2_3 bit to request the PWM period interrupt. PWM flag will be set in every IFCNT2_3[3:0] times of PWM period.
  [7] IFAEN0_1 — PWM Channel 0/1 Interrupt Flag Accumulator Enable Bit
    0=PWM Channel 0/1 interrupt flag accumulator Disabled; 1=PWM Channel 0/1 interrupt flag accumulator Enabled
  [6:4] IFSEL0_1 — PWM Channel 0/1 Interrupt Flag Accumulator Source Select
    0=CNT equal to Zero in channel 0; 1=CNT equal to PERIOD in channel 0; 2=CNT equal to CMPU in channel 0; 3=CNT equal to CMPD in channel 0; 4=CNT equal to Zero in channel 1; 5=CNT equal to PERIOD in channel 1; 6=CNT equal to CMPU in channel 1; 7=CNT equal to CMPD in channel 1
  [3:0] IFCNT0_1 — PWM Channel 0/1 Interrupt Flag Counter. The register sets the count number which defines how many times of PWM Channel 0/1 period occurs to set IFAIF0_1 bit to request the PWM period interrupt. PWM flag will be set in every IFCNT0_1 [3:0] times of PWM period.
0xF8 PWM_ADCTS0 — PWM Trigger ADC Source Select Register 0
  [8n+7] TRGEN{n} (n=0..3) — PWM_CH{n} Trigger ADC enable bit
  [27:24] TRGSEL3 — PWM_CH3 Trigger ADC Source Select
    0=PWM_CH2 zero point; 1=PWM_CH2 period point; 2=PWM_CH2 zero or period point; 3=PWM_CH2 up-count compared point; 4=PWM_CH2 down-count compared point; 5=PWM_CH3 zero point; 6=PWM_CH3 period point; 7=PWM_CH3 zero or period point; 8=PWM_CH3 up-count compared point; 9=PWM_CH3 down-count compared point; 10=PWM_CH0 up-count free trigger compared point; 11=PWM_CH0 down-count free trigger compared point; 12=PWM_CH2 up-count free trigger compared point; 13=PWM_CH2 down-count free trigger compared point; 14=PWM_CH4 up-count free trigger compared point; 15=PWM_CH4 down-count free trigger compared point
  [19:16] TRGSEL2 — PWM_CH2 Trigger ADC Source Select
    values as TRGSEL3
  [11:8] TRGSEL1 — PWM_CH1 Trigger ADC Source Select
    0=PWM_CH0 zero point; 1=PWM_CH0 period point; 2=PWM_CH0 zero or period point; 3=PWM_CH0 up-count compared point; 4=PWM_CH0 down-count compared point; 5=PWM_CH1 zero point; 6=PWM_CH1 period point; 7=PWM_CH1 zero or period point; 8=PWM_CH1 up-count compared point; 9=PWM_CH1 down-count compared point; 10=PWM_CH0 up-count free trigger compared point; 11=PWM_CH0 down-count free trigger compared point; 12=PWM_CH2 up-count free trigger compared point; 13=PWM_CH2 down-count free trigger compared point; 14=PWM_CH4 up-count free trigger compared point; 15=PWM_CH4 down-count free trigger compared point
  [3:0] TRGSEL0 — PWM_CH0 Trigger ADC Source Select
    values as TRGSEL1
0xFC PWM_ADCTS1 — PWM Trigger ADC Source Select Register 1
  [15] TRGEN5 — PWM_CH5 Trigger ADC enable bit
  [11:8] TRGSEL5 — PWM_CH5 Trigger ADC Source Select
    0=PWM_CH4 zero point; 1=PWM_CH4 period point; 2=PWM_CH4 zero or period point; 3=PWM_CH4 up-count compared point; 4=PWM_CH4 down-count compared point; 5=PWM_CH5 zero point; 6=PWM_CH5 period point; 7=PWM_CH5 zero or period point; 8=PWM_CH5 up-count compared point; 9=PWM_CH5 down-count compared point; 10=PWM_CH0 up-count free trigger compared point; 11=PWM_CH0 down-count free trigger compared point; 12=PWM_CH2 up-count free trigger compared point; 13=PWM_CH2 down-count free trigger compared point; 14=PWM_CH4 up-count free trigger compared point; 15=PWM_CH4 down-count free trigger compared point
  [7] TRGEN4 — PWM_CH4 Trigger ADC enable bit
  [3:0] TRGSEL4 — PWM_CH4 Trigger ADC Source Select
    values as TRGSEL5
0x100 PWM_FTCMPDAT0_1 — PWM Free Trigger Compare Register 0/1
  [15:0] FTCMP — PWM Free Trigger Compare Register
0x104 PWM_FTCMPDAT2_3 — PWM Free Trigger Compare Register 2/3
  [15:0] FTCMP — PWM Free Trigger Compare Register
0x108 PWM_FTCMPDAT4_5 — PWM Free Trigger Compare Register 4/5
  [15:0] FTCMP — PWM Free Trigger Compare Register
0x110 PWM_SSCTL — PWM Synchronous Start Control Register
  [8] SSRC — PWM Synchronous Start Source Select Bit
    0=Synchronous start source come from PWM0; 1=Synchronous start source come from PWM1
  [n] SSEN{n} (n=0..5) — PWM Synchronous Start Function Enable Bits. When synchronous start function is enabled, the PWM counter enable register (PWM_CNTEN) can be enabled by writing PWM synchronous start trigger bit (CNTSEN). Each bit n controls the corresponding PWM channel n.
    0=PWM synchronous start function Disabled; 1=PWM synchronous start function Enabled
0x114 PWM_SSTRG wo — PWM Synchronous Start Trigger Register
  [0] CNTSEN — PWM Counter Synchronous Start Enable (Write Only). PMW counter synchronous enable function is used to make selected PWM channels (PWMx_CHn) start counting at the same time. Writing this bit to 1 will also set the counter enable bit (CNTENn, n denotes channel 0 to 5) if correlated PWM channel counter synchronous start function is enabled.
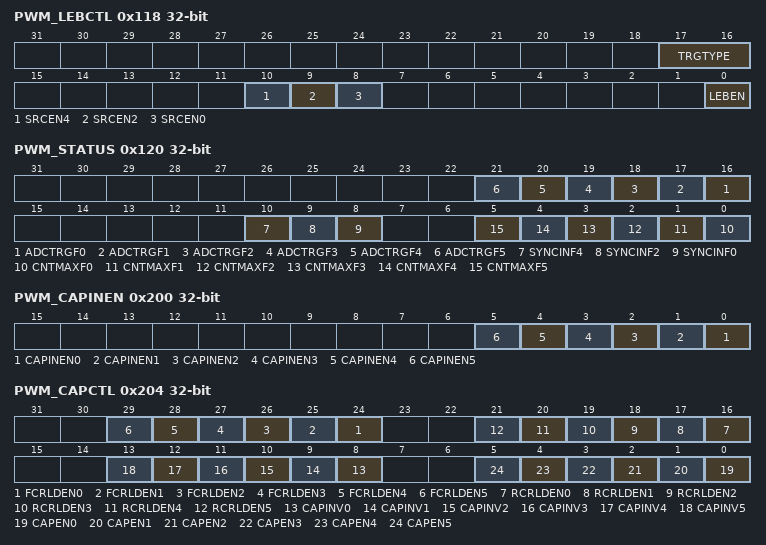
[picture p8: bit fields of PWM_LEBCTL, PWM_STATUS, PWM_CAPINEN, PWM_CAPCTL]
0x118 PWM_LEBCTL — PWM Leading Edge Blanking Control Register
  [17:16] TRGTYPE — PWM Leading Edge Blanking Trigger Type
    0=When detect leading edge blanking source rising edge, blanking counter start counting; 1=When detect leading edge blanking source falling edge, blanking counter start counting; 2=When detect leading edge blanking source rising or falling edge, blanking counter start counting
  [10] SRCEN4 — PWM Leading Edge Blanking Source From PWMx_CH4 Enable Bit
    0=PWM Leading Edge Blanking Source from PWMx_CH4 Disabled; 1=PWM Leading Edge Blanking Source from PWMx_CH4 Enabled
  [9] SRCEN2 — PWM Leading Edge Blanking Source From PWMx_CH2 Enable Bit
    0=PWM Leading Edge Blanking Source from PWMx_CH2 Disabled; 1=PWM Leading Edge Blanking Source from PWMx_CH2 Enabled
  [8] SRCEN0 — PWM Leading Edge Blanking Source From PWMx_CH0 Enable Bit
    0=PWM Leading Edge Blanking Source from PWMx_CH0 Disabled; 1=PWM Leading Edge Blanking Source from PWMx_CH0 Enabled
  [0] LEBEN — PWM Leading Edge Blanking Enable Bit
    0=PWM Leading Edge Blanking Disabled; 1=PWM Leading Edge Blanking Enabled
0x11C PWM_LEBCNT — PWM Leading Edge Blanking Counter Register
  [8:0] LEBCNT — PWM Leading Edge Blanking Counter. This counter value decides leading edge blanking window size.
0x120 PWM_STATUS
  [n+16] ADCTRGF{n} (n=0..5) — ADC Start of Conversion Flag. Each bit n controls the corresponding PWM channel n.
    0=Indicates no ADC start of conversion trigger event has occurred; 1=Indicates an ADC start of conversion trigger event has occurred, software can write 1 to clear this bit
  [10] SYNCINF4 — Input Synchronization Latched Flag. Each bit n controls the corresponding PWM channel n.
    0=Indicates no SYNC_IN event has occurred; 1=Indicates an SYNC_IN event has occurred, software can write 1 to clear this bit
  [9] SYNCINF2 — Input Synchronization Latched Flag. Each bit n controls the corresponding PWM channel n.
    values as SYNCINF4
  [8] SYNCINF0 — Input Synchronization Latched Flag. Each bit n controls the corresponding PWM channel n.
    values as SYNCINF4
  [n] CNTMAXF{n} (n=0..5) — Time-base Counter Equal to 0xFFFF Latched Flag. Each bit n controls the corresponding PWM channel n.
    0=indicates the time-base counter(PWM_CNTn[15:0]) never reached its maximum value 0xFFFF; 1=indicates the time-base counter(PWM_CNTn[15:0]) reached its maximum value, software can write 1 to clear this bit
0x200 PWM_CAPINEN — PWM Capture Input Enable Register
  [all] fields
    0=PWM Channel capture input path Disabled. The input of PWM channel capture function is always regarded as 0; 1=PWM Channel capture input path Enabled. The input of PWM channel capture function comes from correlative multifunction pin
  [n] CAPINEN{n} (n=0..5) — Capture Input Enable Bits. Each bit n controls the corresponding PWM channel n.
0x204 PWM_CAPCTL — PWM Capture Control Register
  [n+24] FCRLDEN{n} (n=0..5) — Falling Capture Reload Enable Bits. Each bit n controls the corresponding PWM channel n.
    0=Falling capture reload counter Disabled; 1=Falling capture reload counter Enabled
  [n+16] RCRLDEN{n} (n=0..5) — Rising Capture Reload Enable Bits. Each bit n controls the corresponding PWM channel n.
    0=Rising capture reload counter Disabled; 1=Rising capture reload counter Enabled
  [n+8] CAPINV{n} (n=0..5) — Capture Inverter Enable Bits. Each bit n controls the corresponding PWM channel n.
    0=Capture source inverter Disabled; 1=Capture source inverter Enabled. Reverse the input signal from GPIO
  [n] CAPEN{n} (n=0..5) — Capture Function Enable Bits. Each bit n controls the corresponding PWM channel n.
    0=Capture function Disabled. RCAPDAT/FCAPDAT registers will not be updated; 1=Capture function Enabled. Capture latched the PWM counter value when detected rising or falling edge of input signal and saved to RCAPDAT (Rising latch) and FCAPDAT (Falling latch) registers
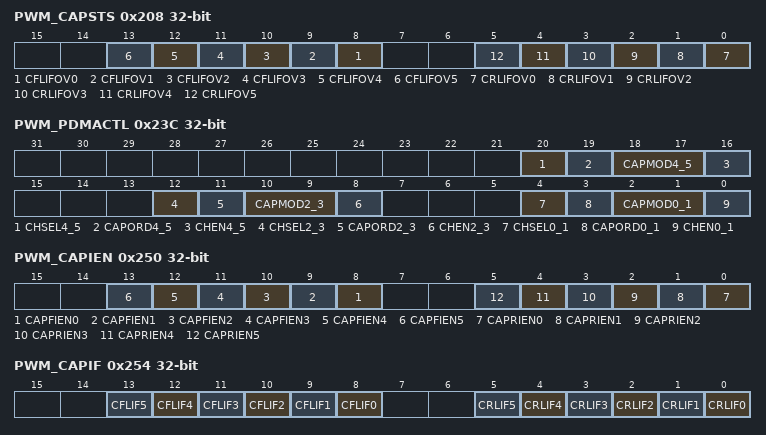
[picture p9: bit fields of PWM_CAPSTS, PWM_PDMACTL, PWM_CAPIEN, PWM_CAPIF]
0x208 PWM_CAPSTS ro — PWM Capture Status Register
  [n+8] CFLIFOV{n} (n=0..5) — Capture Falling Latch Interrupt Flag Overrun Status (Read Only). This flag indicates if falling latch happened when the corresponding CFLIFn(PWM_CAPIF[13:8]) bit is 1. Each bit n controls the corresponding PWM channel n. Note: This bit will be cleared automatically when user clear corresponding CFLIFn bit.
  [n] CRLIFOV{n} (n=0..5) — Capture Rising Latch Interrupt Flag Overrun Status (Read Only). This flag indicates if rising latch happened when the corresponding CRLIFn(PWM_CAPIF[5:0]) bit is 1. Each bit n controls the corresponding PWM channel n. Note: This bit will be cleared automatically when user clear corresponding CRLIFn bit.
{0x20C+8i} PWM_RCAPDAT{i} ro (i=0..5) — PWM Rising Capture Data Register {i}
  [15:0] RCAPDAT — PWM Rising Capture Data Register (Read Only). When rising capture condition happened, the PWM counter value will be saved in this register.
{0x210+8i} PWM_FCAPDAT{i} ro (i=0..5) — PWM Falling Capture Data Register {i}
  [15:0] FCAPDAT — PWM Falling Capture Data Register (Read Only). When falling capture condition happened, the PWM counter value will be saved in this register.
0x23C PWM_PDMACTL — PWM PDMA Control Register
  [20] CHSEL4_5 — Select Channel 4/5 to Do PDMA Transfer
    0=Channel4; 1=Channel5
  [19] CAPORD4_5 — Capture Channel 4/5 Rising/Falling Order. Set this bit to determine whether the PWM_RCAPDAT4/5 or PWM_FCAPDAT4/5 register is the first captured data transferred to memory through PDMA when CAPMOD4_5 bits are set to 0x3.
    0=PWM_FCAPDAT4/5 register is the first captured data to memory; 1=PWM_RCAPDAT4/5 register is the first captured data to memory
  [18:17] CAPMOD4_5 — Select PWM_RCAPDAT4/5 or PWM_FCAPDAT4/5 to Do PDMA Transfer
    1=PWM_RCAPDAT4/5 register; 2=PWM_FCAPDAT4/5 register; 3=Both PWM_RCAPDAT4/5 and PWM_FCAPDAT4/5 registers
  [16] CHEN4_5 — Channel 4/5 PDMA Enable
    0=Channel 4/5 PDMA function Disabled; 1=Channel 4/5 PDMA function Enabled for the channel 4/5 captured data and transfer to memory
  [12] CHSEL2_3 — Select Channel 2/3 to Do PDMA Transfer
    0=Channel2; 1=Channel3
  [11] CAPORD2_3 — Capture Channel 2/3 Rising/Falling Order. Set this bit to determine whether the PWM_RCAPDAT2/3 or PWM_FCAPDAT2/3 register is the first captured data transferred to memory through PDMA when CAPMOD2_3 bits are set to 0x3.
    0=PWM_FCAPDAT2/3 register is the first captured data to memory; 1=PWM_RCAPDAT2/3 register is the first captured data to memory
  [10:9] CAPMOD2_3 — Select PWM_RCAPDAT2/3 or PWM_FCAODAT2/3 to Do PDMA Transfer
    1=PWM_RCAPDAT2/3 register; 2=PWM_FCAPDAT2/3 register; 3=Both PWM_RCAPDAT2/3 and PWM_FCAPDAT2/3 registers
  [8] CHEN2_3 — Channel 2/3 PDMA Enable
    0=Channel 2/3 PDMA function Disabled; 1=Channel 2/3 PDMA function Enabled for the channel 2/3 captured data and transfer to memory
  [4] CHSEL0_1 — Select Channel 0/1 to Do PDMA Transfer
    0=Channel0; 1=Channel1
  [3] CAPORD0_1 — Capture Channel 0/1 Rising/Falling Order. Set this bit to determine whether the PWM_RCAPDAT0/1 or PWM_FCAPDAT0/1 register is the first captured data transferred to memory through PDMA when CAPMOD0_1 bits are set to 0x3.
    0=PWM_FCAPDAT0/1 register is the first captured data to memory; 1=PWM_RCAPDAT0/1 register is the first captured data to memory
  [2:1] CAPMOD0_1 — Select PWM_RCAPDAT0/1 or PWM_FCAPDAT0/1 to Do PDMA Transfer
    1=PWM_RCAPDAT0/1 register; 2=PWM_FCAPDAT0/1 register; 3=Both PWM_RCAPDAT0/1 and PWM_FCAPDAT0/1 registers
  [0] CHEN0_1 — Channel 0/1 PDMA Enable Bit
    0=Channel 0/1 PDMA function Disabled; 1=Channel 0/1 PDMA function Enabled for the channel 0/1 captured data and transfer to memory
0x240 PWM_PDMACAP0_1 ro — PWM Capture Channel 0/1 PDMA Register
  [15:0] CAPBUF — PWM Capture PDMA Register (Read Only). This register is used as a buffer to transfer PWM capture rising or falling data to memory by PDMA.
0x244 PWM_PDMACAP2_3 ro — PWM Capture Channel 2/3 PDMA Register
  fields as PWM_PDMACAP0_1
0x248 PWM_PDMACAP4_5 ro — PWM Capture Channel 4/5 PDMA Register
  fields as PWM_PDMACAP0_1
0x250 PWM_CAPIEN — PWM Capture Interrupt Enable Register
  [n+8] CAPFIEN{n} (n=0..5) — PWM Capture Falling Latch Interrupt Enable Bits. Each bit n controls the corresponding PWM channel n. Note: When Capture with PDMA operating, corresponding channel CAPFIENn bit must be disabled.
    0=Capture falling edge latch interrupt Disabled; 1=Capture falling edge latch interrupt Enabled
  [n] CAPRIEN{n} (n=0..5) — PWM Capture Rising Latch Interrupt Enable Bits. Each bit n controls the corresponding PWM channel n. Note: When Capture with PDMA operating, corresponding channel CAPRIENn bit must be disabled.
    0=Capture rising edge latch interrupt Disabled; 1=Capture rising edge latch interrupt Enabled
0x254 PWM_CAPIF — PWM Capture Interrupt Flag Register
  [n+8] CFLIF{n} (n=0..5) — PWM Capture Falling Latch Interrupt Flag. This bit is writing 1 to clear. Each bit n controls the corresponding PWM channel n. Note: When Capture with PDMA operating, corresponding channel CFLIFn bit will cleared by hardware after PDMA transfer data.
    0=No capture falling latch condition happened; 1=Capture falling latch condition happened, this flag will be set to high
  [n] CRLIF{n} (n=0..5) — PWM Capture Rising Latch Interrupt Flag. This bit is writing 1 to clear. Each bit n controls the corresponding PWM channel n. Note: When Capture with PDMA operating, corresponding channel CRLIFn bit will cleared by hardware after PDMA transfer data.
    0=No capture rising latch condition happened; 1=Capture rising latch condition happened, this flag will be set to high
{0x304+4i} PWM_PBUF{i} ro (i=0..5) — PWM PERIOD{i} Buffer
  [15:0] PBUF — PWM Period Register Buffer (Read Only). Used as PERIOD active register.
{0x31C+4i} PWM_CMPBUF{i} ro (i=0..5) — PWM CMPDAT{i} Buffer
  [15:0] CMPBUF — PWM Comparator Register Buffer (Read Only). Used as CMPDAT active register.
0x334 PWM_CPSCBUF0_1 ro — PWM CLKPSC0_1 Buffer
  [11:0] CPSCBUF — PWM Counter Clock Pre-scale Buffer. Used as PWM counter clock pre-scare active register.
0x338 PWM_CPSCBUF2_3 ro — PWM CLKPSC2_3 Buffer
  fields as PWM_CPSCBUF0_1
0x33C PWM_CPSCBUF4_5 ro — PWM CLKPSC4_5 Buffer
  fields as PWM_CPSCBUF0_1
0x340 PWM_FTCBUF0_1 ro — PWM FTCMPDAT0_1 Buffer
  [15:0] FTCMPBUF — PWM FTCMPDAT Buffer (Read Only). Used as FTCMPDAT active register.
0x344 PWM_FTCBUF2_3 ro — PWM FTCMPDAT2_3 Buffer
  fields as PWM_FTCBUF0_1
0x348 PWM_FTCBUF4_5 ro — PWM FTCMPDAT4_5 Buffer
  fields as PWM_FTCBUF0_1
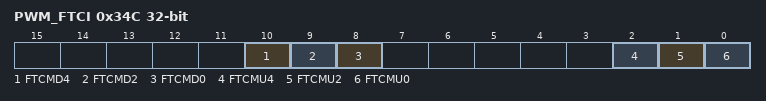
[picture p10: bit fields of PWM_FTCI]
0x34C PWM_FTCI — PWM FTCMPDAT Indicator Register
  [10] FTCMD4 — PWM FTCMPDAT Down Indicator. Indicator will be set to high when FTCMP(PWM_FTCMPDATn[15:0]) bits equal to PERIOD(PWM_PERIODn[15:0]) bits and DIRF(PWM_CNTn[16]) bit is 0, software can write 1 to clear this bit. Each bit n controls the corresponding PWM channel n.
  [9] FTCMD2 — PWM FTCMPDAT Down Indicator. Indicator will be set to high when FTCMP(PWM_FTCMPDATn[15:0]) bits equal to PERIOD(PWM_PERIODn[15:0]) bits and DIRF(PWM_CNTn[16]) bit is 0, software can write 1 to clear this bit. Each bit n controls the corresponding PWM channel n.
  [8] FTCMD0 — PWM FTCMPDAT Down Indicator. Indicator will be set to high when FTCMP(PWM_FTCMPDATn[15:0]) bits equal to PERIOD(PWM_PERIODn[15:0]) bits and DIRF(PWM_CNTn[16]) bit is 0, software can write 1 to clear this bit. Each bit n controls the corresponding PWM channel n.
  [2] FTCMU4 — PWM FTCMPDAT Up Indicator. Indicator will be set to high when FTCMP(PWM_CTCMPDATn[15:0]) bits equal to PERIOD(PWM_PERIODn[15:0]) bits and DIRF(PWM_CNTn[16]) bit is 1, software can write 1 to clear this bit. Each bit n controls the corresponding PWM channel n.
  [1] FTCMU2 — PWM FTCMPDAT Up Indicator. Indicator will be set to high when FTCMP(PWM_CTCMPDATn[15:0]) bits equal to PERIOD(PWM_PERIODn[15:0]) bits and DIRF(PWM_CNTn[16]) bit is 1, software can write 1 to clear this bit. Each bit n controls the corresponding PWM channel n.
  [0] FTCMU0 — PWM FTCMPDAT Up Indicator. Indicator will be set to high when FTCMP(PWM_CTCMPDATn[15:0]) bits equal to PERIOD(PWM_PERIODn[15:0]) bits and DIRF(PWM_CNTn[16]) bit is 1, software can write 1 to clear this bit. Each bit n controls the corresponding PWM channel n.

## PWM1 — PWM Register Map
Base 0x40140000
Registers as PWM0; these are added or differ:
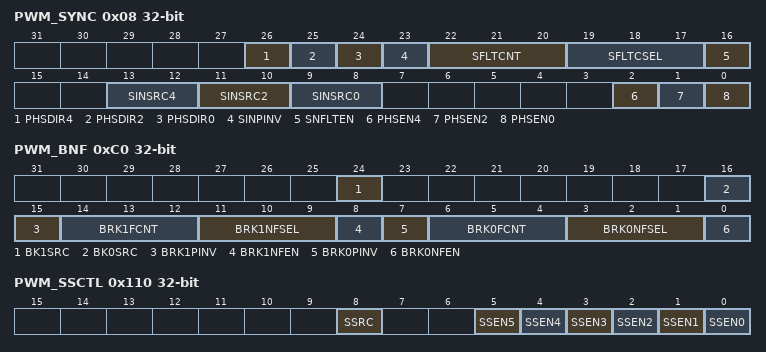
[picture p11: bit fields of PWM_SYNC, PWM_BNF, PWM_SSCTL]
0x08 PWM_SYNC — PWM Synchronization Register
  fields as PWM0.PWM_SYNC
0xC0 PWM_BNF — PWM Brake Noise Filter Register
  fields as PWM0.PWM_BNF
0x110 PWM_SSCTL — PWM Synchronous Start Control Register
  fields as PWM0.PWM_SSCTL
